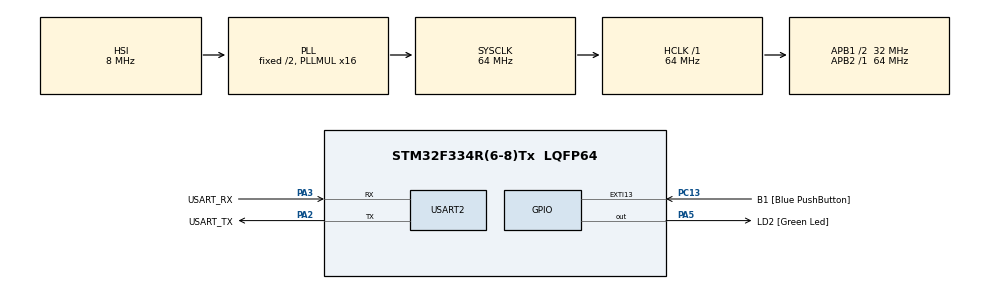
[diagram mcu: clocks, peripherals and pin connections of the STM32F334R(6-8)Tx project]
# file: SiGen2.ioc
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Mcu.Family=STM32F3
Mcu.Name=STM32F334R(6-8)Tx
Mcu.Package=LQFP64
NVIC.PriorityGroup=NVIC_PRIORITYGROUP_0
NVIC.USART2_IRQn=true\:0\:0\:false\:false\:true\:true\:true
PA13.GPIO_Label=TMS
PA13.Mode=Serial_Wire
PA13.Signal=SYS_JTMS-SWDIO
PA14.GPIO_Label=TCK
PA14.Mode=Serial_Wire
PA14.Signal=SYS_JTCK-SWCLK
PA2.GPIO_Label=USART_TX
PA2.Mode=Asynchronous
PA2.Signal=USART2_TX
PA3.GPIO_Label=USART_RX
PA3.Mode=Asynchronous
PA3.Signal=USART2_RX
PA5.GPIO_Label=LD2 [Green Led]
PA5.Signal=GPIO_Output
PB3.GPIO_Label=SWO
PB3.Signal=SYS_JTDO-TRACESWO
PC13.GPIO_Label=B1 [Blue PushButton]
PC13.GPIO_ModeDefaultEXTI=GPIO_MODE_IT_FALLING
PC13.Signal=GPXTI13
PC14\ /\ OSC32_IN.Mode=LSE-External-Oscillator
PC14\ /\ OSC32_IN.Signal=RCC_OSC32_IN
PC15\ /\ OSC32_OUT.GPIO_Label=RCC_OSC32_OUT
PC15\ /\ OSC32_OUT.Mode=LSE-External-Oscillator
PC15\ /\ OSC32_OUT.Signal=RCC_OSC32_OUT
PF0\ /\ OSC_IN.Mode=HSE-External-Clock-Source
PF0\ /\ OSC_IN.Signal=RCC_OSC_IN
PF1\ /\ OSC_OUT.Signal=RCC_OSC_OUT
ProjectManager.HeapSize=0x200
ProjectManager.StackSize=0x400
ProjectManager.TargetToolchain=STM32CubeIDE
RCC.AHBFreq_Value=64000000
RCC.APB1CLKDivider=RCC_HCLK_DIV2
RCC.APB1Freq_Value=32000000
RCC.APB1TimFreq_Value=64000000
RCC.APB2Freq_Value=64000000
RCC.APB2TimFreq_Value=64000000
RCC.CortexFreq_Value=64000000
RCC.FLatency-AdvancedSettings=FLASH_LATENCY_2
RCC.HCLKFreq_Value=64000000
RCC.HSE_VALUE=8000000
RCC.HSI_VALUE=8000000
RCC.PLLMUL=RCC_PLL_MUL16
RCC.SYSCLKFreq_VALUE=64000000
RCC.SYSCLKSourceVirtual=RCC_SYSCLKSOURCE_PLLCLK
USART2.VirtualMode-Asynchronous=VM_ASYNC
board=NUCLEO-F334R8

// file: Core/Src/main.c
/* USER CODE BEGIN Header */
/**
  ******************************************************************************
  * @file           : main.c
  * @brief          : Main program body
  ******************************************************************************
  * @attention
  *
  * <h2><center>&copy; Copyright (c) 2020 STMicroelectronics.
  * All rights reserved.</center></h2>
  *
  * This software component is licensed by ST under BSD 3-Clause license,
  * the "License"; You may not use this file except in compliance with the
  * License. You may obtain a copy of the License at:
  *                        opensource.org/licenses/BSD-3-Clause
  *
  ******************************************************************************
  */
/* USER CODE END Header */

#include "main.h"
#include <string.h>
#include <stdlib.h>
#include <stdio.h>

UART_HandleTypeDef huart2;
UART_HandleTypeDef * huartblbllblb = &huart2;
UART_HandleTypeDef * huartblbllblb2 = &huart2;
UART_HandleTypeDef * huartblbllblb3 = &huart2;
/* USER CODE BEGIN PV */

volatile uint8_t txPending = 0; 			// flaga informujaca o trwajacej transmisji bajtu
// volatile uint8_t framePending = 0;		// ranmka oczekująca

/*
volatile uint8_t frameStage = 0;		// stage - etap
 */

/**
	Wysyłanie stringa na usarta, używając bufora kołowego
 */
void send_string(char* data) {
	// kopiowanie do bufora kołowego danc=ych do wysłania
	int len = strlen(data);
	for (int i = 0; i < len; i++) {
		RingBuffer_write( &transmit_buffer, data[i] );
	}

	__disable_irq(); // wyłączenie globalnych przerwań
	// sprawdzenie czy bufor jest pusty
	if((__HAL_UART_GET_FLAG(&huart2, UART_FLAG_TXE) == SET) && (txPending == 1)) {	// podane warunki są potwierdzeniem,
																					// że transmisja trwa ustawiona
//		if(!RingBuffer_isEmpty( &transmit_buffer)){				// w przypadku podania pustego String-a
			// pobranie z bufora pierwszego znaku do wysłania
			write_b = RingBuffer_read( &transmit_buffer );
			// wysłanie pierwszego znaku
			HAL_StatusTypeDef ret = HAL_UART_Transmit_IT(&huart2, &write_b, 1);
			if(ret == HAL_ERROR){
				txPending = 0;
				transmit_buffer.read_cursor--;
			}
//		}
	}
	__enable_irq(); // włączenie globalnych przerwań
}
/* USER CODE END PV */

void SystemClock_Config(void);
static void MX_GPIO_Init(void);
static void MX_USART2_UART_Init(void);

// stan odbierania ramki
enum frame_state_t{
	  RAMKA_NOT_STARTED,
	  RAMKA_STARTED,
	  RAMKA_FINISHED
};

void przetworz_ramke(char * ramka, int dlugosc){

	// format ramki:  <forma>,<czestotliwosc>,<amplituda>,<faza>
	// suma kontrolna: Liczba zapisana w formie tekstu.
	// Jest sumą wszystkich znaków w przetworzonych elementach.
	ramka[dlugosc]=0;

	// zamień przecinki na 0 i wyszukaj stringi
	char * elements[16]; // tablica stringów stworzona z podzielonej ramki
	int elements_cursor=0;
	elements[elements_cursor]=ramka+0;
	elements_cursor++;
	int i;
	for(i=0;i<dlugosc;i++){
		// czy znak jest przecinkiem
		if(ramka[i]==','){
			ramka[i]=0; // zamien przecinek na 0
			elements[elements_cursor] = ramka+i+1; // miejsce za 0 to kolejny string
			elements_cursor++;
		}
	}

	int N = elements_cursor; // ilosc znalezionych elementow

	// odrzuć ramkę jeśli któryś z elementów jest pusty
	//(string o zerowej dlugosci - pierwszy bajt tego stringa wynosi 0)
	for(i=0;i<N;i++){
		if(elements[i][0] == 0)
			return;
	}

	if(N==4) // wymagana ilosc elementow w ramce
	{

		char waveform = elements[0][0]; // pierwszy bajt pierwszego stringa

		float czestotliwosc = atof(elements[1]); // string do float
		float amplituda = atof(elements[2]);
		float faza = atof(elements[3]);

		char komunikat[64];
		sprintf(komunikat,"\r\n  Ksztalt fali: %c\r\n", waveform);
		send_string(komunikat);

		sprintf(komunikat,"Czestotliwosc: %f\r\n", czestotliwosc);
		send_string(komunikat);
		sprintf(komunikat,"Amplituda: %f\r\n", amplituda);
		send_string(komunikat);
		sprintf(komunikat,"Faza: %f\r\n", faza);
		send_string(komunikat);

	}

	//return;

}
int main(void)
{
  /* MCU Configuration--------------------------------------------------------*/

  /* Reset of all peripherals, Initializes the Flash interface and the Systick. */
  HAL_Init();

  /* Configure the system clock */
  SystemClock_Config();

  /* Initialize all configured peripherals */
  MX_GPIO_Init();
  MX_USART2_UART_Init();
  /* USER CODE BEGIN 2 */

  RingBuffer_init(&recieve_buffer);
  HAL_UART_Receive_IT( &huart2, &read_b, 1 );
  /* USER CODE END 2 */

  // tablica przechwoujaca ramkę
  const int DLUGOSC_RAMKI=64;
  char ramka[DLUGOSC_RAMKI+1];

  // stan odbierania ramki
  enum frame_state_t frame_state=RAMKA_NOT_STARTED;
  int frame_read_cursor;
  /* Infinite loop */
  while (1)
  {
	  	// sprawdź czy przyszedł bajt i o go odczytaj
		if(!RingBuffer_isEmpty(&recieve_buffer)){
			// odczytaj bajt
			unsigned char value = RingBuffer_read(&recieve_buffer);

			// przetwórz bajt w zależności od stanu
			switch(frame_state){
			case RAMKA_FINISHED:
			case RAMKA_NOT_STARTED:
				// szukaj początku ramki
				if(value==':'){
					frame_state = RAMKA_STARTED;
					frame_read_cursor=0;
				}
				break;
			case RAMKA_STARTED:
				if(value==';')
				{
					// zakończ zbieranie ramki
					frame_state = RAMKA_FINISHED;
				}
				else if(value==':'){
					// odrzuć poprzednią ramkę i zacznij zbieranie nowej
					frame_read_cursor=0;
				}
				else{
					if(frame_read_cursor < DLUGOSC_RAMKI){
						ramka[frame_read_cursor] = value;
						frame_read_cursor++;
					}
					else{
						// przepełnienie ramki
						frame_state = RAMKA_NOT_STARTED;
					}
				}
				break;
			}
		}

		// przetwarzanie odebranej ramki
		if(frame_state == RAMKA_FINISHED) {
			przetworz_ramke(ramka, frame_read_cursor);
			frame_state = RAMKA_NOT_STARTED;
		}
  }
  /* USER CODE END 3 */
}

void SystemClock_Config(void)
{
  RCC_OscInitTypeDef RCC_OscInitStruct = {0};
  RCC_ClkInitTypeDef RCC_ClkInitStruct = {0};

  /** Initializes the CPU, AHB and APB busses clocks
  */
  RCC_OscInitStruct.OscillatorType = RCC_OSCILLATORTYPE_HSI;
  RCC_OscInitStruct.HSIState = RCC_HSI_ON;
  RCC_OscInitStruct.HSICalibrationValue = RCC_HSICALIBRATION_DEFAULT;
  RCC_OscInitStruct.PLL.PLLState = RCC_PLL_ON;
  RCC_OscInitStruct.PLL.PLLSource = RCC_PLLSOURCE_HSI;
  RCC_OscInitStruct.PLL.PLLMUL = RCC_PLL_MUL16;
  if (HAL_RCC_OscConfig(&RCC_OscInitStruct) != HAL_OK)
  {
    Error_Handler();
  }
  /** Initializes the CPU, AHB and APB busses clocks
  */
  RCC_ClkInitStruct.ClockType = RCC_CLOCKTYPE_HCLK|RCC_CLOCKTYPE_SYSCLK
                              |RCC_CLOCKTYPE_PCLK1|RCC_CLOCKTYPE_PCLK2;
  RCC_ClkInitStruct.SYSCLKSource = RCC_SYSCLKSOURCE_PLLCLK;
  RCC_ClkInitStruct.AHBCLKDivider = RCC_SYSCLK_DIV1;
  RCC_ClkInitStruct.APB1CLKDivider = RCC_HCLK_DIV2;
  RCC_ClkInitStruct.APB2CLKDivider = RCC_HCLK_DIV1;

  if (HAL_RCC_ClockConfig(&RCC_ClkInitStruct, FLASH_LATENCY_2) != HAL_OK)
  {
    Error_Handler();
  }
}

static void MX_USART2_UART_Init(void)
{

  huart2.Instance = USART2;
  huart2.Init.BaudRate = 9600;
  huart2.Init.WordLength = UART_WORDLENGTH_8B;
  huart2.Init.StopBits = UART_STOPBITS_1;
  huart2.Init.Parity = UART_PARITY_NONE;
  huart2.Init.Mode = UART_MODE_TX_RX;
  huart2.Init.HwFlowCtl = UART_HWCONTROL_NONE;
  huart2.Init.OverSampling = UART_OVERSAMPLING_16;
  huart2.Init.OneBitSampling = UART_ONE_BIT_SAMPLE_DISABLE;
  huart2.AdvancedInit.AdvFeatureInit = UART_ADVFEATURE_NO_INIT;
  if (HAL_UART_Init(&huart2) != HAL_OK)
  {
    Error_Handler();
  }

}

void HAL_UART_RxCpltCallback(UART_HandleTypeDef *huart)
{
  if (huart->Instance == USART2)
  {
	  RingBuffer_write(&recieve_buffer, read_b);
	  HAL_UART_Receive_IT(&huart2, &read_b, 1);
  }
}
void HAL_UART_TxCpltCallback(UART_HandleTypeDef *huart)
{
//	__HAL_UART_CLEAR_FEFLAG(&huart2);					// Tutaj powinno być czyszczenie flagi, jeżeli HAL tego nie zrobił
  if (huart->Instance == USART2)
  {
    if( !RingBuffer_isEmpty(&transmit_buffer) ){
    	write_b = RingBuffer_read( &transmit_buffer );
    	HAL_StatusTypeDef ret = HAL_UART_Transmit_IT(&huart2, &write_b, 1);
		if(ret == HAL_ERROR){
			txPending = 0;
			transmit_buffer.read_cursor--;
		}
    }
  }
}

static void MX_GPIO_Init(void)
{
  GPIO_InitTypeDef GPIO_InitStruct = {0};

  /* GPIO Ports Clock Enable */
  __HAL_RCC_GPIOC_CLK_ENABLE();
  __HAL_RCC_GPIOF_CLK_ENABLE();
  __HAL_RCC_GPIOA_CLK_ENABLE();
  __HAL_RCC_GPIOB_CLK_ENABLE();

  /*Configure GPIO pin Output Level */
  HAL_GPIO_WritePin(LD2_GPIO_Port, LD2_Pin, GPIO_PIN_RESET);

  /*Configure GPIO pin : B1_Pin */
  GPIO_InitStruct.Pin = B1_Pin;
  GPIO_InitStruct.Mode = GPIO_MODE_IT_FALLING;
  GPIO_InitStruct.Pull = GPIO_NOPULL;
  HAL_GPIO_Init(B1_GPIO_Port, &GPIO_InitStruct);

  /*Configure GPIO pin : LD2_Pin */
  GPIO_InitStruct.Pin = LD2_Pin;
  GPIO_InitStruct.Mode = GPIO_MODE_OUTPUT_PP;
  GPIO_InitStruct.Pull = GPIO_NOPULL;
  GPIO_InitStruct.Speed = GPIO_SPEED_FREQ_LOW;
  HAL_GPIO_Init(LD2_GPIO_Port, &GPIO_InitStruct);

}

void Error_Handler(void)
{
}

/************************ (C) COPYRIGHT STMicroelectronics *****END OF FILE****/
